# STM32L412xx register map
File version: 1.0
Registers are 32-bit, read-write, reset 0x0 unless marked. A register's access mark holds for its fields unless they carry their own. Offsets are from the block's base; [hi:lo] are bit positions; {n}, {i} and the like mark numbered series; 'fields as' and 'values as' point back to an identical list.

## TIM6 — TIM
Base 0x40001000
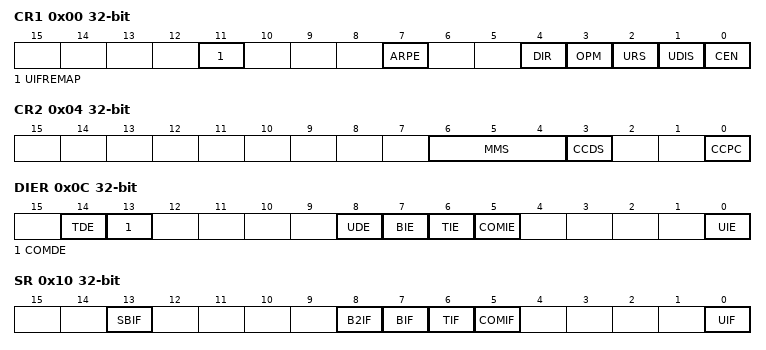
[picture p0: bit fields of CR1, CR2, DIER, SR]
0x00 CR1 — TIM control register 1
  [11] UIFREMAP — Update interrupt flag remap
  [7] ARPE — Auto-reload preload enable
  [4] DIR — Direction
    0=UP (Timer counter counts up); 1=DOWN (Timer counter counts down)
  [3] OPM — One pulse mode
    1=SINGLE (Counter stops counting at the next update event); 0=REPETITIVE (Counter is not stopped at update event)
  [2] URS — Update request source
    0=REGULAR (Counter overflow/underflow, Setting the UG bit or Update generation through the slave mode controller generates an update request); 1=COUNTER (Only counter overflow/underflow generates an update request)
  [1] UDIS — Update disable
  [0] CEN — Counter enable
0x04 CR2 — TIM control register 2
  [6:4] MMS — MMS[2:0] bits (Master Mode Selection)
    0=RESET (UG bit from the TIMx_EGR register is used as trigger output); 1=ENABLE (Counter Enable signal (CNT_EN) is used as trigger output); 2=UPDATE (Update event is used as trigger output); 3=CC1IF (CC1 capture or a compare match is used as trigger output); {v}=OC{v-3}REF (OC{v-3}REF signal is used as trigger output) (v=4..7)
  [3] CCDS — Capture/Compare DMA Selection
    0=CC (CCx DMA request sent when CCx event occurs); 1=UPDATE (CCx DMA requests sent when update event occurs)
  [0] CCPC — Capture/Compare Preloaded Control
0x08 SMCR — TIM slave mode control register
  [3] OCCS — OCREF clear selection
    0=NC (OCREF_CLR_INT is not connected); 1=ETR (OCREF_CLR_INT is connected to ETRF)
0x0C DIER — TIM DMA/interrupt enable register
  [14] TDE — Trigger DMA request enable
  [13] COMDE — COM DMA request enable
  [8] UDE — Update DMA request enable
  [7] BIE — Break interrupt enable
  [6] TIE — Trigger interrupt enable
  [5] COMIE — COM interrupt enable
  [0] UIE — Update interrupt enable
0x10 SR — TIM status register
  [13] SBIF — System Break interrupt Flag
  [8] B2IF — Break 2 interrupt Flag
  [7] BIF — Break interrupt Flag
  [6] TIF — Trigger interrupt Flag
  [5] COMIF — COM interrupt Flag
  [0] UIF — Update interrupt Flag
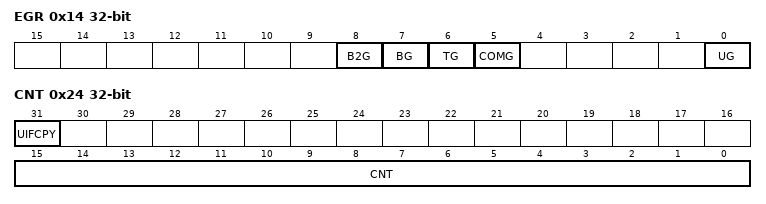
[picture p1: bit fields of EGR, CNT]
0x14 EGR — TIM event generation register
  [8] B2G — Break 2 Generation
  [7] BG — Break Generation
  [6] TG — Trigger Generation
  [5] COMG — Capture/Compare Control Update Generation
  [0] UG — Update Generation
0x24 CNT — TIM counter register
  [31] UIFCPY — Update interrupt flag copy (if UIFREMAP=1)
  [15:0] CNT — Counter Value
0x28 PSC — TIM prescaler
  [15:0] PSC — Prescaler Value
0x2C ARR — TIM auto-reload register
  [15:0] ARR — Actual auto-reload Value
0x4C DMAR — TIM DMA address for full transfer
  [15:0] DMAB — DMA register for burst accesses
0x50 OR1 — TIM option register 1
0x60 OR2 — TIM option register 2
0x64 OR3 — TIM option register 3

## RTC — Real-Time Clock
Base 0x40002800
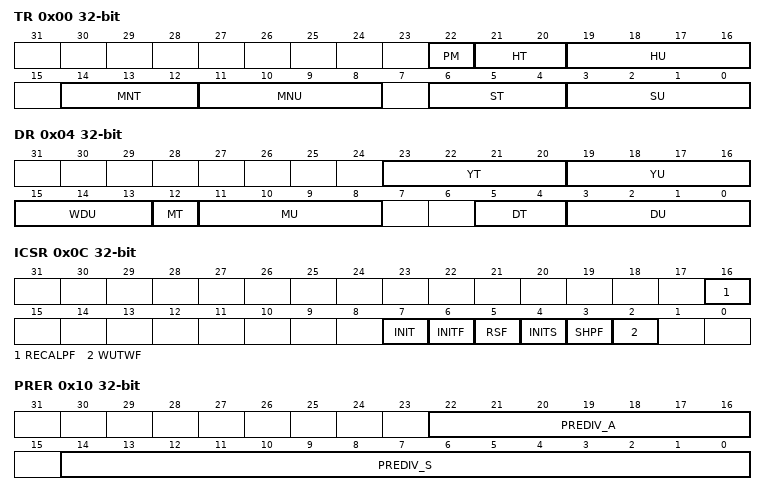
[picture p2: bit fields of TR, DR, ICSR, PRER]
0x00 TR — RTC time register
  [22] PM
    0=AM_OR_24 (AM or 24-hour format); 1=PM
  [21:20] HT
  [19:16] HU
  [14:12] MNT
  [11:8] MNU
  [6:4] ST
  [3:0] SU
0x04 DR — RTC date register
  [23:20] YT, [19:16] YU, [15:13] WDU, [12] MT, [11:8] MU, [5:4] DT, [3:0] DU
0x08 SSR — RTC sub second register
  [15:0] SS
0x0C ICSR — RTC initialization control and status register
  [16] RECALPF, [7] INIT, [6] INITF, [5] RSF, [4] INITS, [3] SHPF, [2] WUTWF
0x10 PRER — RTC prescaler register
  [22:16] PREDIV_A, [14:0] PREDIV_S
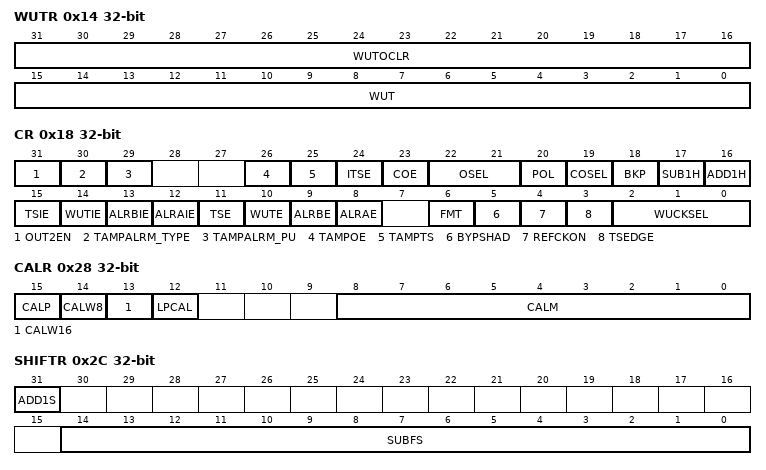
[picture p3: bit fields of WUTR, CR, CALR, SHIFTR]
0x14 WUTR — RTC wakeup timer register
  [31:16] WUTOCLR, [15:0] WUT
0x18 CR — RTC control register
  [31] OUT2EN — RTC_OUT2 output enable
  [30] TAMPALRM_TYPE — TAMPALARM output type
    1=OPENDRAIN (RTC_ALARM is open-drain output); 0=PUSHPULL (RTC_ALARM is push-pull output)
  [29] TAMPALRM_PU — TAMPALARM output pull-up config
  [26] TAMPOE — Tamper detection output enable on TAMPALARM
  [25] TAMPTS — Activate timestamp on tamper detection event
  [24] ITSE — Timestamp on internal event enable
  [23] COE
  [22:21] OSEL
    0=DISABLE (Output disabled); 1=ALMA (Alarm A output enabled); 2=ALMB (Alarm B output enabled); 3=WAKEUP (Wakeup output enabled)
  [20] POL
    0=HIGH (Pin is high when ALRAF/ALRBF/WUTF is asserted (depending on OSEL)); 1=LOW (Pin is low when ALRAF/ALRBF/WUTF is asserted (depending on OSEL))
  [19] COSEL
  [18] BKP
  [17] SUB1H
  [16] ADD1H
  [15] TSIE
  [14] WUTIE
  [13] ALRBIE
  [12] ALRAIE
  [11] TSE
  [10] WUTE
  [9] ALRBE
  [8] ALRAE
  [6] FMT
    0=HOURFORMAT_24HOUR (24 hour/day format); 1=AMPM (AM/PM hour format)
  [5] BYPSHAD
  [4] REFCKON
  [3] TSEDGE
    0=RISING (RTC_TS input rising edge generates a time-stamp event); 1=FALLING (RTC_TS input falling edge generates a time-stamp even)
  [2:0] WUCKSEL
    0=DIV_16 (RTC/16 clock is selected); 1=DIV_8 (RTC/8 clock is selected); 2=DIV_4 (RTC/4 clock is selected); 3=DIV_2 (RTC/2 clock is selected); 4=CKSPRE (ck_spre (usually 1 Hz) clock is selected); 6=CKSPRE_WUT (ck_spre (usually 1 Hz) clock is selected and 2exp16 is added to the WUT counter value)
0x24 WPR — RTC write protection register
  [7:0] KEY
0x28 CALR — RTC calibration register
  [15] CALP
    0=NONE (No RTCCLK pulses are added); 1=SET (One RTCCLK pulse is effectively inserted every 2exp11 pulses (frequency increased by 488.5 ppm))
  [14] CALW8
  [13] CALW16
  [12] LPCAL
  [8:0] CALM
0x2C SHIFTR — RTC shift control register
  [31] ADD1S, [14:0] SUBFS
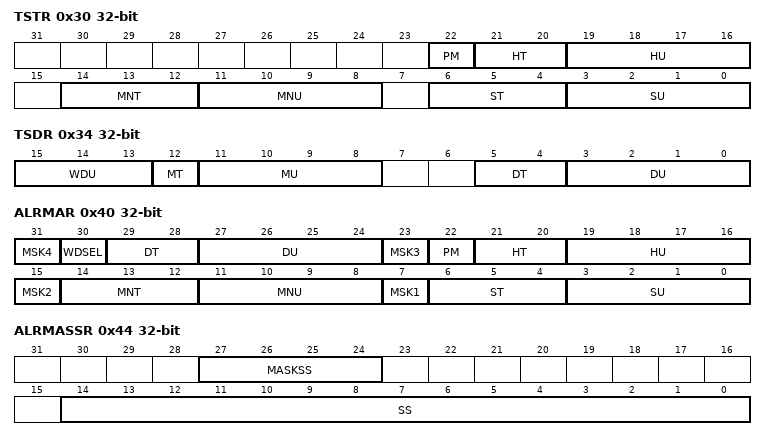
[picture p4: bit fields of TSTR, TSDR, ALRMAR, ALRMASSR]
0x30 TSTR — RTC time stamp time register
  [22] PM
    0=AM (AM or 24-hour format); 1=PM
  [21:20] HT
  [19:16] HU
  [14:12] MNT
  [11:8] MNU
  [6:4] ST
  [3:0] SU
0x34 TSDR — RTC time stamp date register
  [15:13] WDU, [12] MT, [11:8] MU, [5:4] DT, [3:0] DU
0x38 TSSSR — RTC time-stamp sub second register
  [15:0] SS
0x40 ALRMAR — RTC alarm A register
  [8n-1] MSK{n} (n=1..4)
  [30] WDSEL
  [29:28] DT
  [27:24] DU
  [22] PM
    0=AM (AM or 24-hour format); 1=PM
  [21:20] HT
  [19:16] HU
  [14:12] MNT
  [11:8] MNU
  [6:4] ST
  [3:0] SU
0x44 ALRMASSR — RTC alarm A sub second register
  [27:24] MASKSS, [14:0] SS
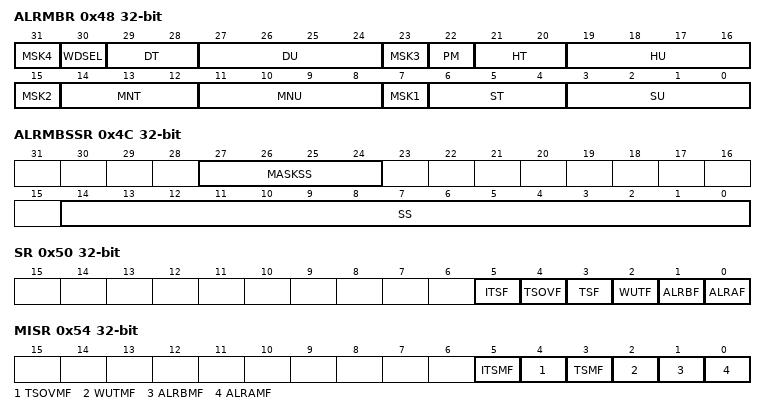
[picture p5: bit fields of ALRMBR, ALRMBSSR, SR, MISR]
0x48 ALRMBR — RTC alarm B register
  fields as ALRMAR
0x4C ALRMBSSR — RTC alarm B sub second register
  [27:24] MASKSS, [14:0] SS
0x50 SR — RTC Status register
  [5] ITSF, [4] TSOVF, [3] TSF, [2] WUTF, [1] ALRBF, [0] ALRAF
0x54 MISR — RTC masked interrupt status register
  [5] ITSMF, [4] TSOVMF, [3] TSMF, [2] WUTMF, [1] ALRBMF, [0] ALRAMF
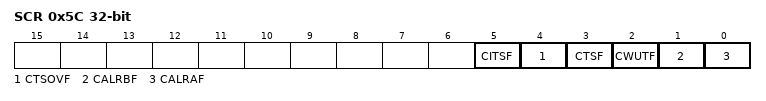
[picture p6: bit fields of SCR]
0x5C SCR — RTC status Clear register
  [5] CITSF, [4] CTSOVF, [3] CTSF, [2] CWUTF, [1] CALRBF, [0] CALRAF
